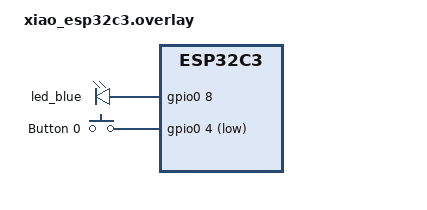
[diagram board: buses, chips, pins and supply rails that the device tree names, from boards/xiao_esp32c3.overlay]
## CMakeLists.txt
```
# SPDX-License-Identifier: Apache-2.0

cmake_minimum_required(VERSION 3.20.0)
find_package(Zephyr REQUIRED HINTS $ENV{ZEPHYR_BASE})
project(button)

target_sources(app PRIVATE src/ble_csc_app.c src/main.cpp src/mag_sens.cpp)

zephyr_library_include_directories(${ZEPHYR_BASE}/samples/bluetooth)
```

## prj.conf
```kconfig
CONFIG_CPP=y
CONFIG_STD_CPP20=y

CONFIG_LOG=y
CONFIG_LOG_BACKEND_UART=y
CONFIG_GPIO=y

# -- disable code optimization so we can debug
CONFIG_DEBUG_OPTIMIZATIONS=n
CONFIG_EXCEPTION_STACK_TRACE=y
CONFIG_DEBUG_INFO=y
CONFIG_ASSERT=y

# CONFIG_SHELL=y
CONFIG_LOG_MODE_IMMEDIATE=y
# -- system debug options
CONFIG_SYS_HEAP_VALIDATE=y
CONFIG_STACK_SENTINEL=y
CONFIG_BUILD_OUTPUT_HEX=y

CONFIG_MAIN_STACK_SIZE=4096
CONFIG_SYSTEM_WORKQUEUE_STACK_SIZE=2048

# Bluetooth feature
CONFIG_ENTROPY_GENERATOR=y
CONFIG_TEST_RANDOM_GENERATOR=y
CONFIG_BT=y
CONFIG_BT_PERIPHERAL=y
CONFIG_BT_DIS=y
CONFIG_BT_DIS_PNP=n
CONFIG_BT_BAS=y
CONFIG_BT_DEVICE_NAME="Zephyr CSC BLE bikemeter"
CONFIG_BT_DEVICE_APPEARANCE=1157
CONFIG_BT_MAX_PAIRED=2
CONFIG_BT_RX_STACK_SIZE=4096
```

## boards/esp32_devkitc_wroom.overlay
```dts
/ {
    aliases {
        led0 = &led_blue;
        magsw = &magsw;
    };

    leds {
        compatible = "gpio-leds";
        led_blue: led_0 {
            gpios = <&gpio0 2 GPIO_ACTIVE_HIGH>;
        };
    };

    buttons {
        compatible = "gpio-keys";
        magsw: magsw0 {
            gpios = <&gpio0 4 (GPIO_ACTIVE_LOW | GPIO_PULL_UP)>;
            label = "Button 0";
        };
    };
};
```

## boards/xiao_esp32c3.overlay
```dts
/ {
    aliases {
        led0 = &led_blue;
        magsw = &magsw;
    };

    leds {
        compatible = "gpio-leds";
        led_blue: led_0 {
            gpios = <&gpio0 8 GPIO_ACTIVE_HIGH>;
        };
    };

    buttons {
        compatible = "gpio-keys";
        magsw: magsw0 {
            gpios = <&gpio0 4 (GPIO_ACTIVE_LOW | GPIO_PULL_UP)>;
            label = "Button 0";
        };
    };
};

&wifi {
    status = "disabled";
};
```

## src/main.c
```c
#include <zephyr/kernel.h>
#include <zephyr/device.h>
#include <zephyr/drivers/gpio.h>
#include <zephyr/sys/util.h>
#include <zephyr/sys/printk.h>
#include <inttypes.h>

#define SLEEP_TIME_MS	1

/*
 * Get button configuration from the devicetree sw0 alias. This is mandatory.
 */
#define SW0_NODE	DT_ALIAS(magsw)
#if !DT_NODE_HAS_STATUS(SW0_NODE, okay)
#error "Unsupported board: sw0 devicetree alias is not defined"
#endif
static const struct gpio_dt_spec button = GPIO_DT_SPEC_GET_OR(SW0_NODE, gpios,
							      {0});
static struct gpio_callback button_cb_data;

/*
 * The led0 devicetree alias is optional. If present, we'll use it
 * to turn on the LED whenever the button is pressed.
 */
static struct gpio_dt_spec led = GPIO_DT_SPEC_GET_OR(DT_ALIAS(led0), gpios,
						     {0});

void button_pressed(const struct device *dev, struct gpio_callback *cb,
		    uint32_t pins)
{
	printk("Button pressed at %" PRIu32 "\n", k_cycle_get_32());
}

int main(void)
{
	int ret;

	if (!gpio_is_ready_dt(&button)) {
		printk("Error: button device %s is not ready\n",
		       button.port->name);
		return 0;
	}

	ret = gpio_pin_configure_dt(&button, GPIO_INPUT);
	if (ret != 0) {
		printk("Error %d: failed to configure %s pin %d\n",
		       ret, button.port->name, button.pin);
		return 0;
	}

	ret = gpio_pin_interrupt_configure_dt(&button,
					      GPIO_INT_EDGE_TO_ACTIVE);
	if (ret != 0) {
		printk("Error %d: failed to configure interrupts on %s pin %d\n",
			ret, button.port->name, button.pin);
		return 0;
	}

	gpio_init_callback(&button_cb_data, button_pressed, BIT(button.pin));
	gpio_add_callback(button.port, &button_cb_data);
	printk("Set up button at %s pin %d\n", button.port->name, button.pin);

	if (led.port && !gpio_is_ready_dt(&led)) {
		printk("Error %d: LED device %s is not ready; ignoring it\n",
		       ret, led.port->name);
		led.port = NULL;
	}
	if (led.port) {
		ret = gpio_pin_configure_dt(&led, GPIO_OUTPUT);
		if (ret != 0) {
			printk("Error %d: failed to configure LED device %s pin %d\n",
			       ret, led.port->name, led.pin);
			led.port = NULL;
		} else {
			printk("Set up LED at %s pin %d\n", led.port->name, led.pin);
		}
	}

	printk("Press the button\n");
	if (led.port) {
		while (1) {
			/* If we have an LED, match its state to the button's. */
			int val = gpio_pin_get_dt(&button);

			if (val >= 0) {
				gpio_pin_set_dt(&led, val);
			}
			k_msleep(SLEEP_TIME_MS);
		}
	}
	return 0;
}
```

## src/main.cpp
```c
#include <zephyr/kernel.h>
#include <zephyr/device.h>
#include <zephyr/drivers/gpio.h>
#include <zephyr/sys/util.h>
#include <zephyr/logging/log.h>
#include <inttypes.h>
#include "../inc/mag_sens.h"
#include "../inc/ble_csc_app.h"

#define SLEEP_TIME_MS	500

#define SW0_NODE	DT_ALIAS(magsw)
#if !DT_NODE_HAS_STATUS(SW0_NODE, okay)
#error "Unsupported board: sw0 devicetree alias is not defined"
#endif

LOG_MODULE_REGISTER(main);

/*
 * Get button configuration from the devicetree sw0 alias. This is mandatory.
 */
static const struct gpio_dt_spec button = GPIO_DT_SPEC_GET_OR(SW0_NODE, gpios,
							      {0});
static struct gpio_callback button_cb_data;

/*
 * The led0 devicetree alias is optional. If present, we'll use it
 * to turn on the LED whenever the button is pressed.
 */
static struct gpio_dt_spec led = GPIO_DT_SPEC_GET_OR(DT_ALIAS(led0), gpios,
						     {0});

int main(void)
{
	int ret;

	// Magnetic switch testing
	mag_sens a(&button);
	a.sens_start();	

	// Enable Bluetooth
	ret = bt_enable(NULL);

	if (ret) {
		LOG_INF("Bluetooth init failed (err %d)\n", ret);
		return 0;
	}
	else
	{
		LOG_INF("Bluetooth initialized\n");
	}
	
	// Callback when Bluetooth is ready
	bt_ready();

	if (led.port && !gpio_is_ready_dt(&led)) {
		LOG_INF("Error %d: LED device %s is not ready; ignoring it\n",
		       ret, led.port->name);
		led.port = NULL;
	}
	if (led.port) {
		ret = gpio_pin_configure_dt(&led, GPIO_OUTPUT);
		if (ret != 0) {
			LOG_INF("Error %d: failed to configure LED device %s pin %d\n",
			       ret, led.port->name, led.pin);
			led.port = NULL;
		} else {
			LOG_INF("Set up LED at %s pin %d\n", led.port->name, led.pin);
		}
	}



	while (1) {
		static uint32_t wheel_rev_ts;
		static uint32_t cum_wheel_rev;

		a.read_wheel_data(&wheel_rev_ts, &cum_wheel_rev);
		LOG_INF("Last wheel timestamp: %d\n", wheel_rev_ts);
		LOG_INF("Cummulative wheel revolutions: %d\n\n", cum_wheel_rev);
		
		// csc_simulation();
		csc_send_attr(&cum_wheel_rev, &wheel_rev_ts, NULL, NULL, true, false);

		k_sleep(K_SECONDS(1));
	}

}
```

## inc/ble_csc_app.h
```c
/**
* @file ble_csc_app.h

* @brief Description in .c
*
* @par 
*
* COPYRIGHT NOTICE: 
*/ 
#ifndef __BLE_CSC_APP_H__
#define __BLE_CSC_APP_H__

#ifdef __cplusplus
extern "C" {
#endif

/* ------> INCLUDES <------ */
#include <stdbool.h>
#include <zephyr/types.h>
#include <stddef.h>
#include <string.h>
#include <errno.h>
#include <zephyr/random/random.h>
#include <zephyr/sys/printk.h>
#include <zephyr/sys/byteorder.h>
#include <zephyr/kernel.h>

#include <zephyr/bluetooth/bluetooth.h>
#include <zephyr/bluetooth/hci.h>
#include <zephyr/bluetooth/conn.h>
#include <zephyr/bluetooth/uuid.h>
#include <zephyr/bluetooth/gatt.h>
#include <zephyr/bluetooth/services/bas.h>

/* ------> MACROS <------ */

// Supported locations for the Cycling Speed and Cadence (CSC) sensor
#define CSC_SUPPORTED_LOCATIONS		{ CSC_LOC_OTHER, \
					  CSC_LOC_FRONT_WHEEL, \
					  CSC_LOC_REAR_WHEEL, \
					  CSC_LOC_LEFT_CRANK, \
					  CSC_LOC_RIGHT_CRANK }

// Features supported by the CSC sensor
#define CSC_FEATURE			(CSC_FEAT_WHEEL_REV | \
					 CSC_FEAT_CRANK_REV | \
					 CSC_FEAT_MULTI_SENSORS)

// CSC Sensor Locations
#define CSC_LOC_OTHER			0x00
#define CSC_LOC_TOP_OF_SHOE		0x01
#define CSC_LOC_IN_SHOE			0x02
#define CSC_LOC_HIP			0x03
#define CSC_LOC_FRONT_WHEEL		0x04
#define CSC_LOC_LEFT_CRANK		0x05
#define CSC_LOC_RIGHT_CRANK		0x06
#define CSC_LOC_LEFT_PEDAL		0x07
#define CSC_LOC_RIGHT_PEDAL		0x08
#define CSC_LOC_FRONT_HUB		0x09
#define CSC_LOC_REAR_DROPOUT		0x0a
#define CSC_LOC_CHAINSTAY		0x0b
#define CSC_LOC_REAR_WHEEL		0x0c
#define CSC_LOC_REAR_HUB		0x0d
#define CSC_LOC_CHEST			0x0e

// CSC Application error codes
#define CSC_ERR_IN_PROGRESS		0x80
#define CSC_ERR_CCC_CONFIG		0x81

// SC Control Point Opcodes
#define SC_CP_OP_SET_CWR		0x01
#define SC_CP_OP_CALIBRATION		0x02
#define SC_CP_OP_UPDATE_LOC		0x03
#define SC_CP_OP_REQ_SUPP_LOC		0x04
#define SC_CP_OP_RESPONSE		0x10

// SC Control Point Response Values
#define SC_CP_RSP_SUCCESS		0x01
#define SC_CP_RSP_OP_NOT_SUPP		0x02
#define SC_CP_RSP_INVAL_PARAM		0x03
#define SC_CP_RSP_FAILED		0x04

// CSC Feature
#define CSC_FEAT_WHEEL_REV		BIT(0)
#define CSC_FEAT_CRANK_REV		BIT(1)
#define CSC_FEAT_MULTI_SENSORS		BIT(2)

// CSC Measurement Flags
#define CSC_WHEEL_REV_DATA_PRESENT	BIT(0)
#define CSC_CRANK_REV_DATA_PRESENT	BIT(1)

/* ------> DATA TYPES <------ */

// Structure for write request to SC Control Point
struct write_sc_ctrl_point_req {
	uint8_t op;
	union {
		uint32_t cwr;
		uint8_t location;
	};
} __packed;

// Structure for SC Control Point indication
struct sc_ctrl_point_ind {
	uint8_t op;
	uint8_t req_op;
	uint8_t status;
	uint8_t data[];
} __packed;

// Structure for CSC Measurement notification
struct csc_measurement_nfy {
	uint8_t flags;
	uint8_t data[];
} __packed;

// Structure for Wheel Revolution data notification
struct wheel_rev_data_nfy {
	uint32_t cwr;
	uint16_t lwet;
} __packed;

// Structure for Crank Revolution data notification
struct crank_rev_data_nfy {
	uint16_t ccr;
	uint16_t lcet;
} __packed;

/* ------> PUBLIC FUNCTION PROTOTYPES <------ */
// Callback when Bluetooth is ready
void bt_ready(void);

// Battery level notification
void bas_notify(void);

// Function to simulate CSC data
void csc_simulation(void);

/**
 * @brief Function to send CSC characteristic measurement data.
 * 
 */
void csc_send_attr(uint32_t * c_wheel_revs, uint32_t * lwet, uint16_t * c_crank_revs, uint32_t * lcet, bool nfy_wheel, bool nfy_crank);

#ifdef __cplusplus
}
#endif

#endif // __BLE_CSC_APP_H__
```

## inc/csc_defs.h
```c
/**
* @file csc_defs.h

* @brief Description in .c
*
* @par 
*
* COPYRIGHT NOTICE: 
*/ 
#ifndef __CSC_DEFS_H__
#define __CSC_DEFS_H__

#ifdef __cplusplus
extern "C" {
#endif

/* ------> INCLUDES <------ */
#include <zephyr/bluetooth/bluetooth.h>

/* ------> MACROS <------ */
// Supported locations for the Cycling Speed and Cadence (CSC) sensor
#define CSC_SUPPORTED_LOCATIONS		{ CSC_LOC_OTHER, \
					  CSC_LOC_FRONT_WHEEL, \
					  CSC_LOC_REAR_WHEEL, \
					  CSC_LOC_LEFT_CRANK, \
					  CSC_LOC_RIGHT_CRANK }

// Features supported by the CSC sensor
#define CSC_FEATURE     CSC_FEAT_WHEEL_REV

// CSC Sensor Locations
#define CSC_LOC_OTHER			0x00
#define CSC_LOC_TOP_OF_SHOE		0x01
#define CSC_LOC_IN_SHOE			0x02
#define CSC_LOC_HIP			0x03
#define CSC_LOC_FRONT_WHEEL		0x04
#define CSC_LOC_LEFT_CRANK		0x05
#define CSC_LOC_RIGHT_CRANK		0x06
#define CSC_LOC_LEFT_PEDAL		0x07
#define CSC_LOC_RIGHT_PEDAL		0x08
#define CSC_LOC_FRONT_HUB		0x09
#define CSC_LOC_REAR_DROPOUT		0x0a
#define CSC_LOC_CHAINSTAY		0x0b
#define CSC_LOC_REAR_WHEEL		0x0c
#define CSC_LOC_REAR_HUB		0x0d
#define CSC_LOC_CHEST			0x0e

// CSC Application error codes
#define CSC_ERR_IN_PROGRESS		0x80
#define CSC_ERR_CCC_CONFIG		0x81

// SC Control Point Opcodes
#define SC_CP_OP_SET_CWR		0x01
#define SC_CP_OP_CALIBRATION		0x02
#define SC_CP_OP_UPDATE_LOC		0x03
#define SC_CP_OP_REQ_SUPP_LOC		0x04
#define SC_CP_OP_RESPONSE		0x10

// SC Control Point Response Values
#define SC_CP_RSP_SUCCESS		0x01
#define SC_CP_RSP_OP_NOT_SUPP		0x02
#define SC_CP_RSP_INVAL_PARAM		0x03
#define SC_CP_RSP_FAILED		0x04

// CSC Feature
#define CSC_FEAT_WHEEL_REV		BIT(0)
#define CSC_FEAT_CRANK_REV		BIT(1)
#define CSC_FEAT_MULTI_SENSORS		BIT(2)

// CSC Measurement Flags
#define CSC_WHEEL_REV_DATA_PRESENT	BIT(0)
#define CSC_CRANK_REV_DATA_PRESENT	BIT(1)

/* ------> DATA TYPES <------ */
// Structure for CSC Measurement notification
struct csc_measurement_nfy {
	uint8_t flags;
	uint8_t data[];
} __packed;

// Structure for Wheel Revolution data notification
struct wheel_rev_data_nfy {
	uint32_t cwr;
	uint16_t lwet;
} __packed;

// Structure for Crank Revolution data notification
struct crank_rev_data_nfy {
	uint16_t ccr;
	uint16_t lcet;
} __packed;

// Structure for SC Control Point indication
struct sc_ctrl_point_ind {
	uint8_t op;
	uint8_t req_op;
	uint8_t status;
	uint8_t data[];
} __packed;

// Structure for write request to SC Control Point
struct write_sc_ctrl_point_req {
	uint8_t op;
	union {
		uint32_t cwr;
		uint8_t location;
	};
} __packed;

/* ------> PUBLIC FUNCTION PROTOTYPES <------ */



#ifdef __cplusplus
}
#endif

#endif // __CSC_DEFS_H__
```

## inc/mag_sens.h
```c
/**
* @file mag_sens.h

* @brief Description in .c
*
* @par 
*
* COPYRIGHT NOTICE: 
*/ 
#ifndef __MAG_SENS_H__
#define __MAG_SENS_H__

#ifdef __cplusplus
extern "C" {
#endif

/* ------> INCLUDES <------ */
#include <zephyr/kernel.h>
#include <zephyr/device.h>
#include <zephyr/drivers/gpio.h>
#include <zephyr/sys/util.h>
#include <zephyr/sys/printk.h>
#include <inttypes.h>

/* ------> MACROS <------ */

/* ------> DATA TYPES <------ */

/* ------> PUBLIC FUNCTION PROTOTYPES <------ */
class mag_sens {
public:
    // Constructor
    mag_sens(const struct gpio_dt_spec *input);

    // Destructor
    ~mag_sens();

    // Read the state of the switch (true for ON, false for OFF)
    bool readSwitchState();

    void sens_start();

    bool read_wheel_data(uint32_t * wheel_ts, uint32_t * wheel_rev);

    void reset_wheel_data();

    // Perform any cleanup or resource release
    void cleanup();

    void enableSwitchInterrupt();
    
    void disableSwitchInterrupt();

private:
    const struct gpio_dt_spec *mag_sw;
    struct gpio_callback switch_cb_data;

    // Initialize the magnetic sensor
    bool init();

    uint32_t last_irq_time = 0;
    // Private callback function for GPIO interrupt
    void switch_int_hndl(const struct device *port,
                         struct gpio_callback *cb,
                         gpio_port_pins_t pins);

    // Static wrapper function for interrupt handler
    static void switch_int_hndl_wrapper(const struct device *port,
                                        struct gpio_callback *cb,
                                        gpio_port_pins_t pins);
    
    struct k_work_delayable switch_debounce_work;
    void debounce_handler(struct k_work *work);
    static void debounce_handler_wrapper(struct k_work *work);

    // Wheel data handler thread
    k_tid_t mag_sens_thread_id;
	struct k_thread mag_sens_thread_data;
    // ISR to thread signal
    struct k_sem mag_sens_sem;

    // Critical section from mag sens thread
    struct k_mutex mag_sens_mutex;
    volatile uint32_t last_wheel_rev_ts;
    volatile uint32_t cum_wheel_rev;
    void event_hndl_thread();
    static void static_event_hndl_thread(void *, void *, void *);
};



#ifdef __cplusplus
}
#endif

#endif // __MAG_SENS_H__
```

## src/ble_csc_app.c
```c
/**
* @file ble_csc_app.c

* @brief TODO
*
* @par TODO
*
* COPYRIGHT NOTICE: 
* 
*/
#include "../inc/ble_csc_app.h"
#include <zephyr/logging/log.h>

/* ------> MACROS <------ */
LOG_MODULE_REGISTER(ble_csc_app);

/* ------> DATA TYPES <------ */

/* ------> PRIVATE FUNCTIONS PROTOTYPES <------ */

// Callback when CCC (Client Characteristic Configuration) for CSC Measurement changes
static void csc_meas_ccc_cfg_changed(const struct bt_gatt_attr *attr,
				     uint16_t value);

// Callback when CCC for SC Control Point changes
static void ctrl_point_ccc_cfg_changed(const struct bt_gatt_attr *attr,
				       uint16_t value);

// Read callback for the Sensor Location characteristic
static ssize_t read_location(struct bt_conn *conn,
			     const struct bt_gatt_attr *attr, void *buf,
			     uint16_t len, uint16_t offset);

// Read callback for the CSC Feature characteristic
static ssize_t read_csc_feature(struct bt_conn *conn,
				const struct bt_gatt_attr *attr, void *buf,
				uint16_t len, uint16_t offset);

// Function to send indication for SC Control Point
static void ctrl_point_ind(struct bt_conn *conn, uint8_t req_op, uint8_t status,
			   const void *data, uint16_t data_len);

// Write callback for SC Control Point
static ssize_t write_ctrl_point(struct bt_conn *conn,
				const struct bt_gatt_attr *attr,
				const void *buf, uint16_t len, uint16_t offset,
				uint8_t flags);

// Function to send CSC Measurement notification
static void measurement_nfy(struct bt_conn *conn, uint32_t cwr, uint16_t lwet,
			    uint16_t ccr, uint16_t lcet);

// Callback when a connection is established
static void connected(struct bt_conn *conn, uint8_t err);

// Callback when a connection is disconnected
static void disconnected(struct bt_conn *conn, uint8_t reason);
/* ------> STATIC DATA <------ */
// Cycling Speed and Cadence Service declaration

// Supported locations array
static uint8_t supported_locations[] = CSC_SUPPORTED_LOCATIONS;
// Current Sensor Location
static uint8_t sensor_location;

// Flag to simulate CSC data TODO
static bool csc_simulate;
// Flag indicating if the Control Point is configured
static bool ctrl_point_configured;

// Cumulative Wheel Revolutions
static uint32_t c_wheel_revs;
// Last Wheel Event Time
static uint16_t lwet;

// Cumulative Crank Revolutions
static uint16_t ccr;
// Last Crank Event Time
static uint16_t lcet;

// Advertising data
static const struct bt_data ad[] = {
	BT_DATA_BYTES(BT_DATA_FLAGS, (BT_LE_AD_GENERAL | BT_LE_AD_NO_BREDR)),
	BT_DATA_BYTES(BT_DATA_UUID16_ALL,
		      BT_UUID_16_ENCODE(BT_UUID_CSC_VAL),
		      BT_UUID_16_ENCODE(BT_UUID_BAS_VAL))
};

// Definition of the Cycling Speed and Cadence (CSC) GATT service
BT_GATT_SERVICE_DEFINE(csc_svc,
	BT_GATT_PRIMARY_SERVICE(BT_UUID_CSC),
	BT_GATT_CHARACTERISTIC(BT_UUID_CSC_MEASUREMENT, BT_GATT_CHRC_NOTIFY,
			       0x00, NULL, NULL, NULL),
	BT_GATT_CCC(csc_meas_ccc_cfg_changed,
		    BT_GATT_PERM_READ | BT_GATT_PERM_WRITE),
	BT_GATT_CHARACTERISTIC(BT_UUID_SENSOR_LOCATION, BT_GATT_CHRC_READ,
			       BT_GATT_PERM_READ, read_location, NULL,
			       &sensor_location),
	BT_GATT_CHARACTERISTIC(BT_UUID_CSC_FEATURE, BT_GATT_CHRC_READ,
			       BT_GATT_PERM_READ, read_csc_feature, NULL, NULL),
	BT_GATT_CHARACTERISTIC(BT_UUID_SC_CONTROL_POINT,
			       BT_GATT_CHRC_WRITE | BT_GATT_CHRC_INDICATE,
			       BT_GATT_PERM_WRITE, NULL, write_ctrl_point,
			       &sensor_location),
	BT_GATT_CCC(ctrl_point_ccc_cfg_changed,
		    BT_GATT_PERM_READ | BT_GATT_PERM_WRITE),
);

// Connection callbacks
BT_CONN_CB_DEFINE(conn_callbacks) = {
	.connected = connected,
	.disconnected = disconnected,
};

/* ------> GLOBAL DATA <------ */

/* ------> PUBLIC FUNCTIONS <------ */

// Callback when Bluetooth is ready
void bt_ready(void)
{
	int err;

	LOG_INF("Bluetooth initialized\n");

	err = bt_le_adv_start(BT_LE_ADV_CONN_NAME, ad, ARRAY_SIZE(ad), NULL, 0);
	if (err) {
		LOG_INF("Advertising failed to start (err %d)\n", err);
		return;
	}

	LOG_INF("Advertising successfully started\n");
}

// Battery level notification
void bas_notify(void)
{
	uint8_t battery_level = bt_bas_get_battery_level();

	battery_level--;

	if (!battery_level) {
		battery_level = 100U;
	}

	bt_bas_set_battery_level(battery_level);
}

// Function to simulate CSC data
void csc_simulation(void)
{
	static uint8_t i;
	uint32_t rand = sys_rand32_get();
	bool nfy_crank = false, nfy_wheel = false;

	/* Measurements don't have to be updated every second */
	if (!(i % 2)) {
		lwet += 1050 + rand % 50;
		c_wheel_revs += 2U;
		nfy_wheel = true;
	}

	if (!(i % 3)) {
		lcet += 1000 + rand % 50;
		ccr += 1U;
		nfy_crank = true;
	}

	/*
	 * In typical applications, the CSC Measurement characteristic is
	 * notified approximately once per second. This interval may vary
	 * and is determined by the Server and not required to be configurable
	 * by the Client.
	 */
	measurement_nfy(NULL, nfy_wheel ? c_wheel_revs : 0, nfy_wheel ? lwet : 0,
			nfy_crank ? ccr : 0, nfy_crank ? lcet : 0);

	/*
	 * The Last Crank Event Time value and Last Wheel Event Time roll over
	 * every 64 seconds.
	 */
	if (!(i % 64)) {
		lcet = 0U;
		lwet = 0U;
		i = 0U;
	}

	i++;
}

void csc_send_attr(uint32_t * c_wheel_revs, uint32_t * lwet, uint16_t * c_crank_revs, uint32_t * lcet, bool nfy_wheel, bool nfy_crank)
{
	/*
	 * In typical applications, the CSC Measurement characteristic is
	 * notified approximately once per second. This interval may vary
	 * and is determined by the Server and not required to be configurable
	 * by the Client.
	 */
	measurement_nfy(NULL, nfy_wheel ? *c_wheel_revs : 0, nfy_wheel ? (uint16_t)	*lwet : 0, nfy_crank ? *c_crank_revs : 0, nfy_crank ? (uint16_t)*lcet : 0);

}

/* ------> PRIVATE FUNCTIONS <------ */
// Callback when CCC (Client Characteristic Configuration) for CSC Measurement changes
static void csc_meas_ccc_cfg_changed(const struct bt_gatt_attr *attr,
				     uint16_t value)
{
	csc_simulate = value == BT_GATT_CCC_NOTIFY;
}

// Callback when CCC for SC Control Point changes
static void ctrl_point_ccc_cfg_changed(const struct bt_gatt_attr *attr,
				       uint16_t value)
{
	ctrl_point_configured = value == BT_GATT_CCC_INDICATE;
}

// Read callback for the Sensor Location characteristic
static ssize_t read_location(struct bt_conn *conn,
			     const struct bt_gatt_attr *attr, void *buf,
			     uint16_t len, uint16_t offset)
{
	uint8_t *value = attr->user_data;

	return bt_gatt_attr_read(conn, attr, buf, len, offset, value,
				 sizeof(*value));
}

// Read callback for the CSC Feature characteristic
static ssize_t read_csc_feature(struct bt_conn *conn,
				const struct bt_gatt_attr *attr, void *buf,
				uint16_t len, uint16_t offset)
{
	uint16_t csc_feature = CSC_FEATURE;

	return bt_gatt_attr_read(conn, attr, buf, len, offset,
				 &csc_feature, sizeof(csc_feature));
}

// Function to send indication for SC Control Point
static void ctrl_point_ind(struct bt_conn *conn, uint8_t req_op, uint8_t status,
			   const void *data, uint16_t data_len);


// Write callback for SC Control Point
static ssize_t write_ctrl_point(struct bt_conn *conn,
				const struct bt_gatt_attr *attr,
				const void *buf, uint16_t len, uint16_t offset,
				uint8_t flags)
{
	const struct write_sc_ctrl_point_req *req = buf;
	uint8_t status;
	int i;

	if (!ctrl_point_configured) {
		return BT_GATT_ERR(CSC_ERR_CCC_CONFIG);
	}

	if (!len) {
		return BT_GATT_ERR(BT_ATT_ERR_INVALID_ATTRIBUTE_LEN);
	}

	switch (req->op) {
	case SC_CP_OP_SET_CWR:
		if (len != sizeof(req->op) + sizeof(req->cwr)) {
			status = SC_CP_RSP_INVAL_PARAM;
			break;
		}

		c_wheel_revs = sys_le32_to_cpu(req->cwr);
		status = SC_CP_RSP_SUCCESS;
		break;
	case SC_CP_OP_UPDATE_LOC:
		if (len != sizeof(req->op) + sizeof(req->location)) {
			status = SC_CP_RSP_INVAL_PARAM;
			break;
		}

		/* Break if the requested location is the same as the current one */
		if (req->location == sensor_location) {
			status = SC_CP_RSP_SUCCESS;
			break;
		}

		/* Pre-set status */
		status = SC_CP_RSP_INVAL_PARAM;

		/* Check if the requested location is supported */
		for (i = 0; i < ARRAY_SIZE(supported_locations); i++) {
			if (supported_locations[i] == req->location) {
				sensor_location = req->location;
				status = SC_CP_RSP_SUCCESS;
				break;
			}
		}

		break;
	case SC_CP_OP_REQ_SUPP_LOC:
		if (len != sizeof(req->op)) {
			status = SC_CP_RSP_INVAL_PARAM;
			break;
		}

		/* Indicate supported locations and return */
		ctrl_point_ind(conn, req->op, SC_CP_RSP_SUCCESS,
			       &supported_locations,
			       sizeof(supported_locations));

		return len;
	default:
		status = SC_CP_RSP_OP_NOT_SUPP;
	}

	ctrl_point_ind(conn, req->op, status, NULL, 0);

	return len;
}

// Function to send indication for SC Control Point
static void ctrl_point_ind(struct bt_conn *conn, uint8_t req_op, uint8_t status,
			   const void *data, uint16_t data_len)
{
	struct sc_ctrl_point_ind *ind;
	uint8_t buf[sizeof(*ind) + data_len];

	ind = (void *) buf;
	ind->op = SC_CP_OP_RESPONSE;
	ind->req_op = req_op;
	ind->status = status;

	/* Send data (supported locations) if present */
	if (data && data_len) {
		memcpy(ind->data, data, data_len);
	}

	// Notify the SC Control Point characteristic
	bt_gatt_notify(conn, &csc_svc.attrs[8], buf, sizeof(buf));
}

// Function to send CSC Measurement notification
static void measurement_nfy(struct bt_conn *conn, uint32_t cwr, uint16_t lwet,
			    uint16_t ccr, uint16_t lcet)
{
	struct csc_measurement_nfy *nfy;
	uint8_t buf[sizeof(*nfy) +
		    (cwr ? sizeof(struct wheel_rev_data_nfy) : 0) +
		    (ccr ? sizeof(struct crank_rev_data_nfy) : 0)];
	uint16_t len = 0U;

	nfy = (void *) buf;
	nfy->flags = 0U;

	/* Send Wheel Revolution data if present */
	if (cwr) {
		struct wheel_rev_data_nfy data;

		nfy->flags |= CSC_WHEEL_REV_DATA_PRESENT;
		data.cwr = sys_cpu_to_le32(cwr);
		data.lwet = sys_cpu_to_le16(lwet);

		memcpy(nfy->data, &data, sizeof(data));
		len += sizeof(data);
	}

	/* Send Crank Revolution data if present */
	if (ccr) {
		struct crank_rev_data_nfy data;

		nfy->flags |= CSC_CRANK_REV_DATA_PRESENT;
		data.ccr = sys_cpu_to_le16(ccr);
		data.lcet = sys_cpu_to_le16(lcet);

		memcpy(nfy->data + len, &data, sizeof(data));
	}

	// Notify the CSC Measurement characteristic
	bt_gatt_notify(NULL, &csc_svc.attrs[1], buf, sizeof(buf));
}

// Callback when a connection is established
static void connected(struct bt_conn *conn, uint8_t err)
{
	if (err) {
		LOG_INF("Connection failed (err 0x%02x)\n", err);
	} else {
		LOG_INF("Connected\n");
	}
}

// Callback when a connection is disconnected
static void disconnected(struct bt_conn *conn, uint8_t reason)
{
	LOG_INF("Disconnected (reason 0x%02x)\n", reason);
}

/* ------> INTERRUPT HANDLERS <------ */
```

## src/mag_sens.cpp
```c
/**
* @file mag_sens.cpp
*
* @brief Implementation file for the mag_sens class.
*
* @par
*
* COPYRIGHT NOTICE:
*/
#include "../inc/mag_sens.h"
#include <zephyr/kernel.h>
#include <zephyr/logging/log.h>

/* ------> MACROS <------ */
LOG_MODULE_REGISTER(mag_sens);

#define DEBOUNCE_TIMEOUT_MS 150
#define STACK_SIZE 2048
#define THREAD_PRIORITY 5

K_THREAD_STACK_DEFINE(threadStack, STACK_SIZE);

/* ------> DATA TYPES <------ */

/* ------> PRIVATE FUNCTIONS PROTOTYPES <------ */

/* ------> STATIC DATA <------ */

/* ------> GLOBAL DATA <------ */

/* ------> PUBLIC FUNCTIONS <------ */

/**
 * @brief Constructor for the MagSense class.
 *
 * @param input Pointer to the GPIO device specification.
 */
mag_sens::mag_sens(const struct gpio_dt_spec *input) {
    mag_sw = input;

    // Initialize magnetic sensor
    if (!init()) {
        LOG_INF("Failed to initialize magnetic sensor\n");
        // Handle initialization failure if needed
    }

    mag_sens_thread_id = k_thread_create(&mag_sens_thread_data, 
		threadStack,
		K_THREAD_STACK_SIZEOF(threadStack),
		mag_sens::static_event_hndl_thread,
		this, NULL, NULL,
		THREAD_PRIORITY, 0, K_FOREVER);

    k_sem_init(&mag_sens_sem,0, 1);
}

void mag_sens::sens_start()
{
    k_thread_start(mag_sens_thread_id);
}
/**
 * @brief Read the state of the switch.
 *
 * @return True if the switch is ON, false if OFF.
 */
bool mag_sens::readSwitchState() {
    bool state;
    state = gpio_pin_get_dt(mag_sw);
    return state;
}

/**
 * @brief Returns last revolution timestamp (ms) and cumulative wheel 
 *        revolutions.
 * 
 * @param wheel_ts Pointer to last wheel revolution timestamp variable.
 * @param cum_wheel_rev Pointer to total wheel revolution counter variable.
 */
bool mag_sens::read_wheel_data(uint32_t * wheel_ts, uint32_t * wheel_rev)
{
    bool ret=false;

    if (k_mutex_lock(&mag_sens_mutex, K_NO_WAIT) == 0)
    {
        *wheel_ts = last_wheel_rev_ts;
        *wheel_rev = cum_wheel_rev;
        k_mutex_unlock(&mag_sens_mutex);
        ret = true;
    }

    return ret;
}

void mag_sens::reset_wheel_data()
{
    if (k_mutex_lock(&mag_sens_mutex, K_NO_WAIT))
    {
        cum_wheel_rev = 0;
        k_mutex_unlock(&mag_sens_mutex);
    }
}

/**
 * @brief Destructor for the MagSense class.
 */
mag_sens::~mag_sens() {
    // Destructor TODO
    return;
}

/* ------> PRIVATE FUNCTIONS <------ */

/**
 * @brief Perform any cleanup or resource release.
 */
void mag_sens::cleanup() {
    // Perform any cleanup or resource release
    LOG_INF("Cleaning up magnetic sensor\n");
    // Add cleanup logic if needed
}

/**
 * @brief Initialize the magnetic sensor.
 *
 * @return True if initialization is successful, false otherwise.
 */
bool mag_sens::init() {
    int ret;

    // Check if GPIO device is ready
    if (!gpio_is_ready_dt(mag_sw)) {
        LOG_INF("Error: button device %s is not ready\n",
               mag_sw->port->name);
        return false;
    }

    // Configure GPIO pin as input
    ret = gpio_pin_configure_dt(mag_sw, GPIO_INPUT);
    if (ret != 0) {
        LOG_INF("Error %d: failed to configure %s pin %d\n",
               ret, mag_sw->port->name, mag_sw->pin);
        return false;
    }

    // Configure GPIO interrupts
    ret = gpio_pin_interrupt_configure_dt(mag_sw,
                                          GPIO_INT_EDGE_TO_INACTIVE);
    if (ret != 0) {
        LOG_INF("Error %d: failed to configure interrupts on %s pin %d\n",
            ret, mag_sw->port->name, mag_sw->pin);
        return false;
    }

    // Initialize GPIO callback and add it
    gpio_init_callback(&switch_cb_data, switch_int_hndl_wrapper, BIT(mag_sw->pin));
    gpio_add_callback(mag_sw->port, &switch_cb_data);

    // Initialize debounce work and return success
    k_work_init_delayable(&switch_debounce_work, debounce_handler_wrapper);

    // Initialize variables and lock mutex
    k_mutex_init(&mag_sens_mutex);
    last_wheel_rev_ts = 0;
    cum_wheel_rev = 0;
    return true;
}

/**
 * @brief Wrapper for switch_int_hndl to use non-static member function.
 *
 * @param port Pointer to the GPIO device structure.
 * @param cb Pointer to the GPIO callback structure.
 * @param pins GPIO port pins.
 */
void mag_sens::switch_int_hndl_wrapper(const struct device *port,
                                        struct gpio_callback *cb,
                                        gpio_port_pins_t pins) {
    // Get the instance from the callback data
    mag_sens *instance = CONTAINER_OF(cb, mag_sens, switch_cb_data);

    // Call the non-static member function
    instance->switch_int_hndl(port, cb, pins);
}

void mag_sens::event_hndl_thread()
{
    while (true)
    {
        k_sem_take(&mag_sens_sem, K_FOREVER);
        
        /* Lock the mutex before updating shared variables */
        k_mutex_lock(&mag_sens_mutex, K_FOREVER);

        /* Update shared variables */
        last_wheel_rev_ts = k_uptime_get_32();
        cum_wheel_rev++;

        LOG_INF("Event LWT: %d\n", last_wheel_rev_ts);
        LOG_INF("Event CWR: %d\n\n", cum_wheel_rev);

        /* Unlock the mutex */
        k_mutex_unlock(&mag_sens_mutex);
    }
    
}

void mag_sens::static_event_hndl_thread(void *object, void *, void *)
{
    auto threadObject = reinterpret_cast<mag_sens*>(object);
	threadObject->event_hndl_thread();
}

/**
 * @brief Enable switch interrupt.
 */
void mag_sens::enableSwitchInterrupt() {
    LOG_INF("Mag switch int enable\n");
    gpio_pin_interrupt_configure_dt(mag_sw,
                                    GPIO_INT_EDGE_TO_INACTIVE);
}

/**
 * @brief Disable switch interrupt.
 */
void mag_sens::disableSwitchInterrupt() {
    LOG_INF("Mag switch int disable\n");
    gpio_pin_interrupt_configure_dt(mag_sw,
                                    GPIO_INT_DISABLE);
}

/* ------> INTERRUPT HANDLERS <------ */

/**
 * @brief Work handler function for switch debouncing.
 *
 * @param work Pointer to the k_work structure.
 */
void mag_sens::debounce_handler(struct k_work *work) {
    // Enable switch interrupt after debounce timeout
    enableSwitchInterrupt();
}

/**
 * @brief Wrapper for debounce_handler to use non-static member function.
 *
 * @param work Pointer to the k_work structure.
 */
void mag_sens::debounce_handler_wrapper(struct k_work *work) {
    // Get the instance from the work item
    mag_sens* instance = CONTAINER_OF(work, mag_sens, switch_debounce_work);

    // Call the non-static member function
    instance->debounce_handler(work);
}

/**
 * @brief Switch interrupt handler.
 *
 * @param port Pointer to the GPIO device structure.
 * @param cb Pointer to the GPIO callback structure.
 * @param pins GPIO port pins.
 */
void mag_sens::switch_int_hndl(const struct device *port,
                                 struct gpio_callback *cb,
                                 gpio_port_pins_t pins) {
    // Disable interrupts
    disableSwitchInterrupt();
    
    uint32_t curr_time = k_uptime_get_32();

    if ( (curr_time - last_irq_time) > DEBOUNCE_TIMEOUT_MS && (last_irq_time != 0))
    {
        // critical section
        k_sem_give(&mag_sens_sem);
    }

    last_irq_time = curr_time;
    // Schedule debounce work after a timeout
    k_work_schedule(&switch_debounce_work, K_MSEC(DEBOUNCE_TIMEOUT_MS));
}
```
